# C7X256V_CORE0_DRU_SET_7C404000h register map
Vendor: Texas Instruments
Peripheral module from a debugger description file (folder am62D).
Registers are 64-bit, write-only, reset 0x0 unless marked. A register's access mark holds for its fields unless they carry their own. Offsets are as the file gives them; lines under a group give offsets from that group; [hi:lo] are bit positions; {n}, {i} and the like mark numbered series; 'fields as' and 'values as' point back to an identical list; <NAME> marks a mode.

## dru_set
0x00 dru_set_dru_shared_evt_set — DRU Shared Event Set Register
  [0] PROT_ERR — Set the Prot Error event
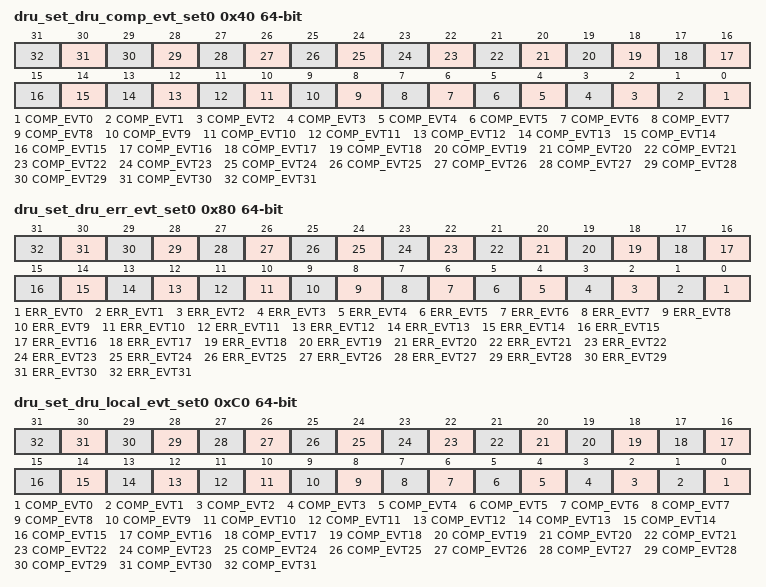
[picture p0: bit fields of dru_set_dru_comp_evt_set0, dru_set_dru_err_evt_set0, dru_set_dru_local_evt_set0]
0x40 dru_set_dru_comp_evt_set0 — DRU Completion Event Set Register
  [n] COMP_EVT{n} (n=0..31) — Set the Completion Event for channel {n}
0x80 dru_set_dru_err_evt_set0 — DRU Error Event Set Register
  [n] ERR_EVT{n} (n=0..31) — Set the Error Event for channel {n}
0xC0 dru_set_dru_local_evt_set0 — DRU Local Event Set Register
  [n] COMP_EVT{n} (n=0..31) — Set the Local Event for channel {n}
